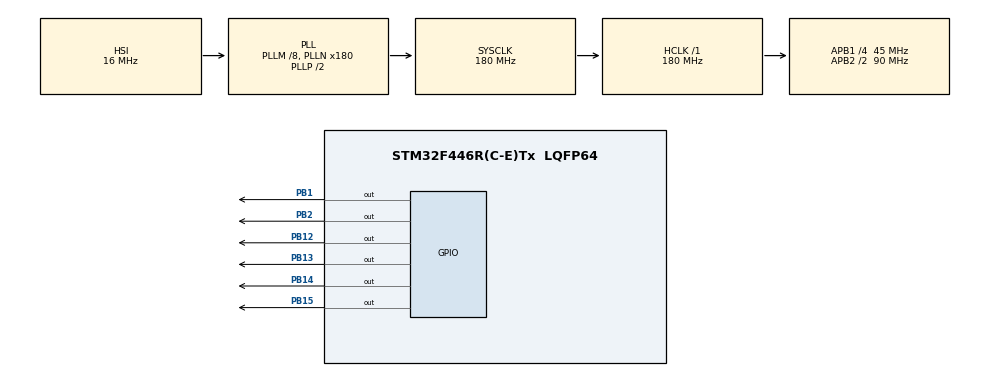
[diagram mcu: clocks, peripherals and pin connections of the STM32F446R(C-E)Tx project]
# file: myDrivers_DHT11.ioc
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Mcu.Family=STM32F4
Mcu.Name=STM32F446R(C-E)Tx
Mcu.Package=LQFP64
NVIC.PriorityGroup=NVIC_PRIORITYGROUP_4
PA13.Mode=Serial_Wire
PA13.Signal=SYS_JTMS-SWDIO
PA14.Mode=Serial_Wire
PA14.Signal=SYS_JTCK-SWCLK
PB1.GPIO_Speed=GPIO_SPEED_FREQ_VERY_HIGH
PB1.Signal=GPIO_Output
PB12.GPIO_Speed=GPIO_SPEED_FREQ_VERY_HIGH
PB12.Signal=GPIO_Output
PB13.GPIO_Speed=GPIO_SPEED_FREQ_VERY_HIGH
PB13.Signal=GPIO_Output
PB14.GPIO_Speed=GPIO_SPEED_FREQ_VERY_HIGH
PB14.Signal=GPIO_Output
PB15.GPIO_Speed=GPIO_SPEED_FREQ_VERY_HIGH
PB15.Signal=GPIO_Output
PB2.GPIO_Speed=GPIO_SPEED_FREQ_VERY_HIGH
PB2.Signal=GPIO_Output
PC14-OSC32_IN.Mode=LSE-External-Oscillator
PC14-OSC32_IN.Signal=RCC_OSC32_IN
PC15-OSC32_OUT.Mode=LSE-External-Oscillator
PC15-OSC32_OUT.Signal=RCC_OSC32_OUT
PH0-OSC_IN.Mode=HSE-External-Oscillator
PH0-OSC_IN.Signal=RCC_OSC_IN
PH1-OSC_OUT.Mode=HSE-External-Oscillator
PH1-OSC_OUT.Signal=RCC_OSC_OUT
ProjectManager.HeapSize=0x200
ProjectManager.StackSize=0x400
ProjectManager.TargetToolchain=STM32CubeIDE
RCC.AHBFreq_Value=180000000
RCC.APB1CLKDivider=RCC_HCLK_DIV4
RCC.APB1Freq_Value=45000000
RCC.APB1TimFreq_Value=90000000
RCC.APB2CLKDivider=RCC_HCLK_DIV2
RCC.APB2Freq_Value=90000000
RCC.APB2TimFreq_Value=180000000
RCC.CortexFreq_Value=180000000
RCC.HCLKFreq_Value=180000000
RCC.PLLM=8
RCC.PLLN=180
RCC.SYSCLKFreq_VALUE=180000000
RCC.SYSCLKSource=RCC_SYSCLKSOURCE_PLLCLK
RCC.USBFreq_Value=180000000
RCC.VCOOutputFreq_Value=360000000
board=custom

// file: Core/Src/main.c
/* USER CODE BEGIN Header */
/**
  ******************************************************************************
  * @file           : main.c
  * @brief          : Main program body
  ******************************************************************************
  * @attention
  *
  * Copyright (c) 2025 STMicroelectronics.
  * All rights reserved.
  *
  * This software is licensed under terms that can be found in the LICENSE file
  * in the root directory of this software component.
  * If no LICENSE file comes with this software, it is provided AS-IS.
  *
  ******************************************************************************
  */
/* USER CODE END Header */
#include "main.h"

/* USER CODE BEGIN Includes */
#include "DHT11.h"
#include "LCD.h"
#include "stdio.h"
/* USER CODE END Includes */

/* USER CODE BEGIN PTD */
extern DHT11_TypeDef_t DHT11;
extern SensorState_t sensorState;

char bufferDistance_temperature[50];
char bufferDistance_humidity[50];
/* USER CODE END PTD */

void SystemClock_Config(void);
static void MX_GPIO_Init(void);

int main(void)
{

  /* MCU Configuration--------------------------------------------------------*/

  /* Reset of all peripherals, Initializes the Flash interface and the Systick. */
  HAL_Init();

  /* Configure the system clock */
  SystemClock_Config();

  /* Initialize all configured peripherals */
  MX_GPIO_Init();
  /* USER CODE BEGIN 2 */
  DHT11_init(GPIOC, GPIO_PIN_3);

  LCD_init(GPIOB, GPIO_PIN_15,
		         GPIOB, GPIO_PIN_1,
				 GPIOB, GPIO_PIN_2,
				 GPIOB, GPIO_PIN_12,
				 GPIOB, GPIO_PIN_14,
				 GPIOB, GPIO_PIN_13);
  LCD_clear();
  /* USER CODE END 2 */

  /* Infinite loop */
  while (1)
  {

    /* USER CODE BEGIN 3 */
	  DHT11_start();
	  sensorState = DHT11_checkResponse();
	  DHT11_readFrame(sensorState);

	  sprintf(bufferDistance_temperature, "Temperature = %.0f", DHT11.temperature);
	  sprintf(bufferDistance_humidity, "Humidity    = %.0f", DHT11.humidity);

	  LCD_clear();
	  LCD_setCursor(1, 1);
	  LCD_writeString(bufferDistance_temperature);
	  DELAY_MS(1);
	  LCD_setCursor(2, 1);
	  LCD_writeString(bufferDistance_humidity);
	  DELAY_MS(250);
  }
  /* USER CODE END 3 */
}

void SystemClock_Config(void)
{
  RCC_OscInitTypeDef RCC_OscInitStruct = {0};
  RCC_ClkInitTypeDef RCC_ClkInitStruct = {0};

  /** Configure the main internal regulator output voltage
  */
  __HAL_RCC_PWR_CLK_ENABLE();
  __HAL_PWR_VOLTAGESCALING_CONFIG(PWR_REGULATOR_VOLTAGE_SCALE1);

  /** Initializes the RCC Oscillators according to the specified parameters
  * in the RCC_OscInitTypeDef structure.
  */
  RCC_OscInitStruct.OscillatorType = RCC_OSCILLATORTYPE_HSI;
  RCC_OscInitStruct.HSIState = RCC_HSI_ON;
  RCC_OscInitStruct.HSICalibrationValue = RCC_HSICALIBRATION_DEFAULT;
  RCC_OscInitStruct.PLL.PLLState = RCC_PLL_ON;
  RCC_OscInitStruct.PLL.PLLSource = RCC_PLLSOURCE_HSI;
  RCC_OscInitStruct.PLL.PLLM = 8;
  RCC_OscInitStruct.PLL.PLLN = 180;
  RCC_OscInitStruct.PLL.PLLP = RCC_PLLP_DIV2;
  RCC_OscInitStruct.PLL.PLLQ = 2;
  RCC_OscInitStruct.PLL.PLLR = 2;
  if (HAL_RCC_OscConfig(&RCC_OscInitStruct) != HAL_OK)
  {
    Error_Handler();
  }

  /** Activate the Over-Drive mode
  */
  if (HAL_PWREx_EnableOverDrive() != HAL_OK)
  {
    Error_Handler();
  }

  /** Initializes the CPU, AHB and APB buses clocks
  */
  RCC_ClkInitStruct.ClockType = RCC_CLOCKTYPE_HCLK|RCC_CLOCKTYPE_SYSCLK
                              |RCC_CLOCKTYPE_PCLK1|RCC_CLOCKTYPE_PCLK2;
  RCC_ClkInitStruct.SYSCLKSource = RCC_SYSCLKSOURCE_PLLCLK;
  RCC_ClkInitStruct.AHBCLKDivider = RCC_SYSCLK_DIV1;
  RCC_ClkInitStruct.APB1CLKDivider = RCC_HCLK_DIV4;
  RCC_ClkInitStruct.APB2CLKDivider = RCC_HCLK_DIV2;

  if (HAL_RCC_ClockConfig(&RCC_ClkInitStruct, FLASH_LATENCY_5) != HAL_OK)
  {
    Error_Handler();
  }
}

static void MX_GPIO_Init(void)
{
  GPIO_InitTypeDef GPIO_InitStruct = {0};

  /* GPIO Ports Clock Enable */
  __HAL_RCC_GPIOC_CLK_ENABLE();
  __HAL_RCC_GPIOH_CLK_ENABLE();
  __HAL_RCC_GPIOB_CLK_ENABLE();
  __HAL_RCC_GPIOA_CLK_ENABLE();

  /*Configure GPIO pin Output Level */
  HAL_GPIO_WritePin(GPIOC, GPIO_PIN_3, GPIO_PIN_RESET);

  /*Configure GPIO pin Output Level */
  HAL_GPIO_WritePin(GPIOB, GPIO_PIN_1|GPIO_PIN_2|GPIO_PIN_12|GPIO_PIN_13
                          |GPIO_PIN_14|GPIO_PIN_15, GPIO_PIN_RESET);

  /*Configure GPIO pin : PC3 */
  GPIO_InitStruct.Pin = GPIO_PIN_3;
  GPIO_InitStruct.Mode = GPIO_MODE_OUTPUT_PP;
  GPIO_InitStruct.Pull = GPIO_NOPULL;
  GPIO_InitStruct.Speed = GPIO_SPEED_FREQ_VERY_HIGH;
  HAL_GPIO_Init(GPIOC, &GPIO_InitStruct);

  /*Configure GPIO pins : PB1 PB2 PB12 PB13
                           PB14 PB15 */
  GPIO_InitStruct.Pin = GPIO_PIN_1|GPIO_PIN_2|GPIO_PIN_12|GPIO_PIN_13
                          |GPIO_PIN_14|GPIO_PIN_15;
  GPIO_InitStruct.Mode = GPIO_MODE_OUTPUT_PP;
  GPIO_InitStruct.Pull = GPIO_NOPULL;
  GPIO_InitStruct.Speed = GPIO_SPEED_FREQ_VERY_HIGH;
  HAL_GPIO_Init(GPIOB, &GPIO_InitStruct);

}

void Error_Handler(void)
{
  __disable_irq();
  while (1)
  {
  }
}
